VERSION ""

NS_ :

BS_:

BU_: DBG DRIVER MOTOR SENSOR_BRIDGE GEO

BO_ 101 CAR_ACTION: 1 SENSOR_BRIDGE
 SG_ CAR_ACTION_cmd : 0|8@1+ (1,0) [0|0] "" DRIVER

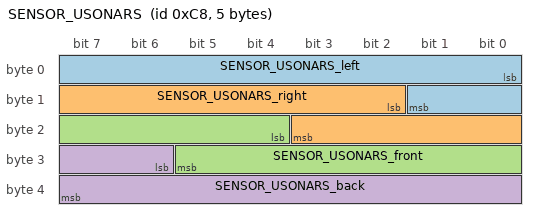
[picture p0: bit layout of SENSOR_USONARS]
BO_ 200 SENSOR_USONARS: 5 SENSOR_BRIDGE
 SG_ SENSOR_USONARS_left : 0|10@1+ (1,0) [0|0] "cm" DRIVER
 SG_ SENSOR_USONARS_right : 10|10@1+ (1,0) [0|0] "cm" DRIVER
 SG_ SENSOR_USONARS_front : 20|10@1+ (1,0) [0|0] "cm" DRIVER
 SG_ SENSOR_USONARS_back : 30|10@1+ (1,0) [0|0] "cm" DRIVER

BO_ 300 DRIVER_STEER_SPEED: 2 DRIVER
 SG_ DRIVER_STEER_direction : 0|8@1- (1,0) [-2|2] "" MOTOR, SENSOR_BRIDGE
 SG_ DRIVER_STEER_move_speed: 8|8@1- (1,0) [-10|10] "" MOTOR, SENSOR_BRIDGE

BO_ 401 GEO_COMPASS: 5 GEO
 SG_ GEO_COMPASS_current_heading : 0|16@1+ (1,0) [0|360] “degree” DRIVER, SENSOR_BRIDGE
 SG_ GEO_COMPASS_desitination_heading : 16|16@1+ (1,0) [0|360] “degree” DRIVER, SENSOR_BRIDGE
 SG_ GEO_COMPASS_distance: 32|8@1+ (1,0) [0, 255] “unit” DRIVER, SENSOR_BRIDGE

BO_ 500 BRIDGE_GPS: 8 SENSOR_BRIDGE
 SG_ BRIDGE_GPS_latitude : 0|32@1- (1E-007,-91.1111111) [-91.1111111|91.1111111] "" DRIVER
 SG_ BRIDGE_GPS_longitude : 32|32@1- (1E-007,-181.1111111) [-181.1111111|181.1111111] "" DRIVER

BO_ 600 MOTOR_SPEED: 4 MOTOR
 SG_ MOTOR_SPEED_info : 0|16@1- (0.01,-30.01) [-30.01|30.01] "mph" DRIVER, SENSOR_BRIDGE
 SG_ MOTOR_SPEED_pwm : 16|16@1+ (0.01, 0) [0.01|20.01] "pwm" DRIVER, SENSOR_BRIDGE

BO_ 700 TEST_BUTTON: 1 SENSOR_BRIDGE
 SG_ TEST_BUTTON_press : 0|8@1+ (1,0) [0|0] "" MOTOR

BO_ 800 HEADLIGHT: 1 SENSOR_BRIDGE
 SG_ HEADLIGHT_SWITCH : 0|8@1+ (1,0) [0|0] "" DRIVER

CM_ BU_ DRIVER "The driver controller driving the car";
CM_ BU_ MOTOR "The motor controller of the car";
CM_ BU_ SENSOR_BRIDGE "The sensor and bridge controller of the car";
CM_ BU_ GEO "The geo controller of the car";
CM_ BO_ 100 "Sync message used to synchronize the controllers";
CM_ SG_ 100 DRIVER_HEARTBEAT_cmd "Heartbeat command from the driver";

BA_DEF_ "BusType" STRING ;
BA_DEF_ BO_ "GenMsgCycleTime" INT 0 0;
BA_DEF_ SG_ "FieldType" STRING ;

BA_DEF_DEF_ "BusType" "CAN";
BA_DEF_DEF_ "FieldType" "";
BA_DEF_DEF_ "GenMsgCycleTime" 0;

BA_ "GenMsgCycleTime" BO_ 100 1000;
BA_ "GenMsgCycleTime" BO_ 200 50;
BA_ "FieldType" SG_ 100 DRIVER_HEARTBEAT_cmd "DRIVER_HEARTBEAT_cmd";

BA_ "FieldType" SG_ 300 DRIVER_STEER_direction "DRIVER_STEER_direction";

VAL_ 300 DRIVER_STEER_direction -2 "DRIVER_STEER_direction_HARD_LEFT" -1 "DRIVER_STEER_direction_SOFT_LEFT" 0 "DRIVER_STEER_direction_STRAIGHT" 1 "DRIVER_STEER_direction_SOFT_RIGHT" 2 "DRIVER_STEER_direction_HARD_RIGHT" ;
